# alb32r003x register map
Vendor: ALB; Series: ALB RT SoC
CPU: ALB XF, little endian
Registers are 32-bit, access not given, reset 0x0 unless marked. A register's access mark holds for its fields unless they carry their own. Offsets are from the block's base; [hi:lo] are bit positions; {n}, {i} and the like mark numbered series.

## ECAP1
Base 0x21020000
Same registers: ECAP2 0x21020400
0x00 TSCTR
  [31:0] TSCTR — Active 32-bit counter register that is used as the capture time-base
0x04 CTRPHS
  [31:0] CTRPHS_CFG — Counter phase value register that can be programmed for phase
0x08 CAP1
  [31:0] CAP1 — This register can be loaded (written) by:
0x0C CAP2
  [31:0] CAP2 — This register can be loaded (written) by:
0x10 CAP3
  [31:0] CAP3 — In CAP mode, this is a time-stamp capture register.
0x14 CAP4
  [31:0] CAP4 — In CAP mode, this is a time-stamp capture register.
0x24 ECCTL0
  [6:0] ECCTL0_INPUTSEL_CFG — Capture input source select bits
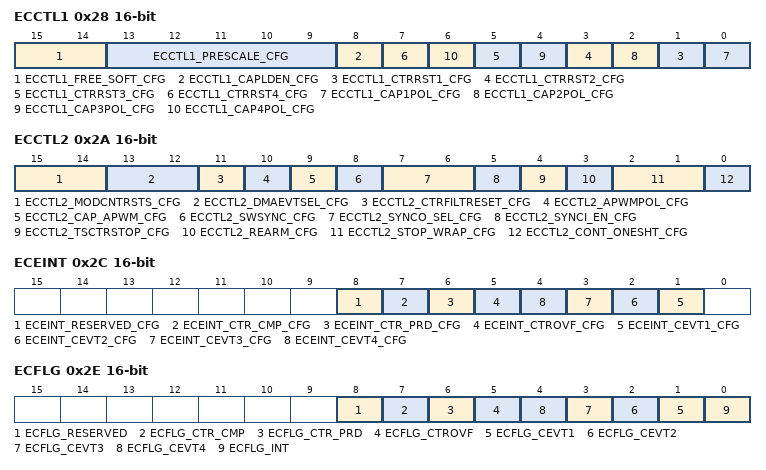
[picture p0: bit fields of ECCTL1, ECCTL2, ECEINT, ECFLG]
0x28 ECCTL1 16-bit
  [15:14] ECCTL1_FREE_SOFT_CFG — Emulation Control
  [13:9] ECCTL1_PRESCALE_CFG — Event Filter prescale select
  [8] ECCTL1_CAPLDEN_CFG — Enable Loading of CAP1-4 registers on a capture event. Note that
  [2n-1] ECCTL1_CTRRST{n}_CFG (n=1..4) — Counter Reset on Capture Event {n}
  [2n-2] ECCTL1_CAP{n}POL_CFG (n=1..4) — Capture Event {n} Polarity select
0x2A ECCTL2 16-bit
  [15:14] ECCTL2_MODCNTRSTS_CFG — This bit field reads current status on modulo counter
  [13:12] ECCTL2_DMAEVTSEL_CFG — DMA event select
  [11] ECCTL2_CTRFILTRESET_CFG — Reset Bit
  [10] ECCTL2_APWMPOL_CFG — APWM output polarity select. This is applicable only in APWM operating mode.
  [9] ECCTL2_CAP_APWM_CFG — CAP/APWM operating mode select
  [8] ECCTL2_SWSYNC_CFG — Software-forced Counter (TSCTR) Synchronizer. This provides the user a method to generate a synchronization
  [7:6] ECCTL2_SYNCO_SEL_CFG — Sync-Out Select
  [5] ECCTL2_SYNCI_EN_CFG — Counter (TSCTR) Sync-In select mode
  [4] ECCTL2_TSCTRSTOP_CFG — Time Stamp (TSCTR) Counter Stop (freeze) Control
  [3] ECCTL2_REARM_CFG — Re-Arming Control. Note: The re-arm function is valid in one shot or continuous mode
  [2:1] ECCTL2_STOP_WRAP_CFG — Stop value for one-shot mode. This is the number (between 1-4) of captures allowed to occur before the
  [0] ECCTL2_CONT_ONESHT_CFG — Continuous or one-shot mode control (applicable only in capture mode)
0x2C ECEINT 16-bit
  [8] ECEINT_RESERVED_CFG
  [7] ECEINT_CTR_CMP_CFG — Counter Equal Compare Interrupt Enable
  [6] ECEINT_CTR_PRD_CFG — Counter Equal Period Interrupt Enable
  [5] ECEINT_CTROVF_CFG — Counter Overflow Interrupt Enable
  [n] ECEINT_CEVT{n}_CFG (n=1..4) — Capture Event {n} Interrupt Enable
0x2E ECFLG 16-bit
  [8] ECFLG_RESERVED
  [7] ECFLG_CTR_CMP — Compare Equal Compare Status Flag. This flag is active only in APWM mode.
  [6] ECFLG_CTR_PRD — Counter Equal Period Status Flag. This flag is only active in APWM mode.
  [5] ECFLG_CTROVF — Counter Overflow Status Flag. This flag is active in CAP and APWM mode.
  [n] ECFLG_CEVT{n} (n=1..4) — Capture Event {n} Status Flag This flag is only active in CAP mode.
  [0] ECFLG_INT — Global Interrupt Status Flag
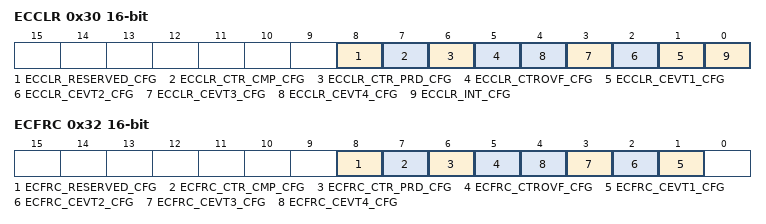
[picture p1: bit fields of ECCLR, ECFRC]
0x30 ECCLR 16-bit
  [8] ECCLR_RESERVED_CFG
  [7] ECCLR_CTR_CMP_CFG — Counter Equal Compare Status Clear
  [6] ECCLR_CTR_PRD_CFG — Counter Equal Period Status Clear
  [5] ECCLR_CTROVF_CFG — Counter Overflow Status Clear
  [n] ECCLR_CEVT{n}_CFG (n=1..4) — Capture Event {n} Status Clear
  [0] ECCLR_INT_CFG — ECAP Global Interrupt Status Clear
0x32 ECFRC 16-bit
  [8] ECFRC_RESERVED_CFG
  [7] ECFRC_CTR_CMP_CFG — Force Counter Equal Compare Interrupt. This event is only active in
  [6] ECFRC_CTR_PRD_CFG — Force Counter Equal Period Interrupt. This event is only active in
  [5] ECFRC_CTROVF_CFG — Force Counter Overflow
  [n] ECFRC_CEVT{n}_CFG (n=1..4) — Force Capture Event {n}. This event is only active in CAP mode.

## ECAP3
Base 0x21020000
Registers as ECAP1; these are added or differ:
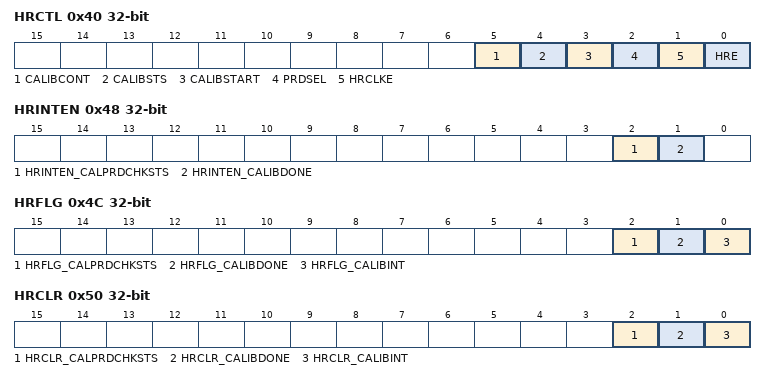
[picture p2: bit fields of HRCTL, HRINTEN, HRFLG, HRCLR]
0x40 HRCTL
  [5] CALIBCONT — Continuous mode Calibration Select Bit:
  [4] CALIBSTS — Calibration status Bit:
  [3] CALIBSTART — Calibration start Bit:
  [2] PRDSEL — Calibration Period Match Select Bit:
  [1] HRCLKE — High Resolution Clock Enable Bit:
  [0] HRE — High Resolution Enable Bit:
0x48 HRINTEN
  [2] HRINTEN_CALPRDCHKSTS — Calibration Period Check status Interrupt Enable:
  [1] HRINTEN_CALIBDONE — Calibration done Interrupt Enable:
0x4C HRFLG
  [2] HRFLG_CALPRDCHKSTS — Calibration period check status Flag Bit:
  [1] HRFLG_CALIBDONE — Calibration Done Interrupt Flag Bit:
  [0] HRFLG_CALIBINT — Global calibration Interrupt Status Flag:
0x50 HRCLR
  [2] HRCLR_CALPRDCHKSTS — Calibration period check status Flag Bit:
  [1] HRCLR_CALIBDONE — Calibration Done Interrupt Flag Bit:
  [0] HRCLR_CALIBINT — reserved
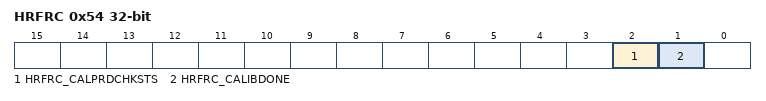
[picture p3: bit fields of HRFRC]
0x54 HRFRC
  [2] HRFRC_CALPRDCHKSTS — Force CALPRDCHKSTS flag:
  [1] HRFRC_CALIBDONE — Force CALIBDONE flag:
0x58 HRCALPRD
  [31:0] HRCALPRD — Register to program calibration period. The period value is matched
0x5C HRSYSCLKCTR
  [31:0] HRSYSCLKCTR — Current SYSCLK counter value
0x60 HRSYSCLKCAP
  [31:0] HRSYSCLKCAP — HRSYSCLKCTR is captures into this register at end of calibration
0x64 HRCLKCTR
  [31:0] HRCLKCTR — Current HRCLK counter value
0x68 HRCLKCAP
  [31:0] HRCLKCAP — HRCLKCTR is captures into this register at end of calibration cycle.
